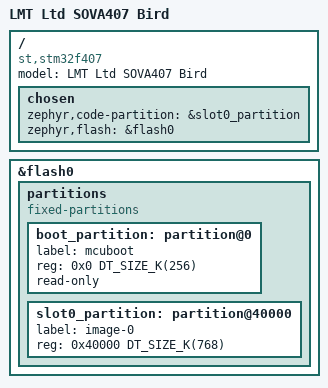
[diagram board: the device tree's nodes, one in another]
/dts-v1/;
#include <st/f4/stm32f407Xg.dtsi>
#include <st/f4/stm32f407v(e-g)tx-pinctrl.dtsi>
#include "SOVA4x.dts"

/ {
	model = "LMT Ltd SOVA407 Bird";
	compatible = "st,stm32f407";
	
	chosen {
		zephyr,code-partition = &slot0_partition;
		zephyr,flash = &flash0;
	};
};

&flash0 {
	partitions {
		compatible = "fixed-partitions";
		#address-cells = <1>;
		#size-cells = <1>;

		/* for bootloader */
		boot_partition: partition@0 {
			label = "mcuboot";
			reg = <0x0 DT_SIZE_K(256)>;
			read-only;
		};
		/* application image slot */
		slot0_partition: partition@40000 {
			label = "image-0";
			reg = <0x40000 DT_SIZE_K(768)>;
		};
	};
};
